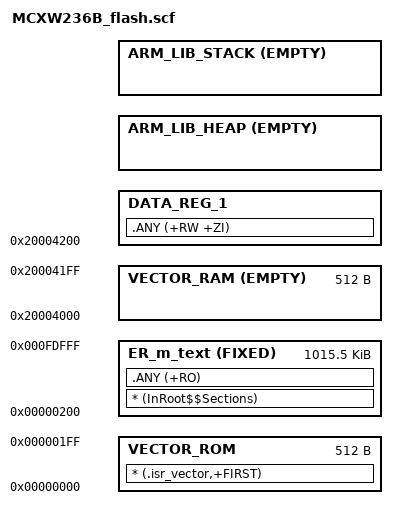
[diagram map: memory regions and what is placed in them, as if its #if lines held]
#!armclang --target=arm-arm-none-eabi -march=armv8-m.main -E -x c
/*
** ###################################################################
**     Processors:          MCXW236BIHNAR
**                          MCXW236BIUKAR
**
**     Compiler:            Keil ARM C/C++ Compiler
**     Reference manual:    MCXW23x User manual Rev.0.1  1 September 2022
**     Version:             rev. 1.0, 2022-03-08
**     Build:               b241118
**
**     Abstract:
**         Linker file for the Keil ARM C/C++ Compiler
**
**     Copyright 2016 Freescale Semiconductor, Inc.
**     Copyright 2016-2025 NXP
**     SPDX-License-Identifier: BSD-3-Clause
**
**     http:                 www.nxp.com
**     mail:                 support@nxp.com
**
** ###################################################################
*/


/* Sizes */
#if (defined(__stack_size__))
  #define Stack_Size                   __stack_size__
#else
  #define Stack_Size                   0x0500
#endif

#if (defined(__heap_size__))
  #define Heap_Size                    __heap_size__
#else
  #define Heap_Size                    0x0400
#endif

#define __ram_vector_table_size__      0x00000200

#define  m_interrupts_start            0x00000000
#define  m_interrupts_size             0x00000200

#define m_text_start                   0x00000200
#define m_text_size                    0x000FDE00

#define m_interrupts_ram_start         0x20004000
#define m_interrupts_ram_size          __ram_vector_table_size__

/* 112k (SRAM0 = 16k, SRAM1 = 32k, SRAM2 = 64K) RAM to fit data segment */
/* First  512B (from 0x20004000 until 0x20004200) ram is used to put vector table */
/* The reset of ram is used for data memory */
#define  m_data_start                  (m_interrupts_ram_start + m_interrupts_ram_size)
#define  m_data_size                   (0x0001A000 - m_interrupts_ram_size)

LR_m_text m_interrupts_start m_interrupts_size+m_text_size {   ; load region size_region

  VECTOR_ROM m_interrupts_start m_interrupts_size { ; load address = execution address
    * (.isr_vector,+FIRST)
  }

  VECTOR_RAM m_interrupts_ram_start EMPTY m_interrupts_ram_size {
  }

  ER_m_text m_text_start FIXED m_text_size {
    * (InRoot$$Sections)
    .ANY (+RO)
  }
  DATA_REG_1 m_data_start m_data_size-Stack_Size-Heap_Size
  {
    .ANY (+RW +ZI)
  }
  ARM_LIB_HEAP +0 EMPTY Heap_Size {    ; Heap region growing up
  }
  ARM_LIB_STACK m_data_start+m_data_size EMPTY -Stack_Size { ; Stack region growing down
  }

  ScatterAssert(ImageLimit(ARM_LIB_STACK) <= 0x20020000); Check for RAM overflow. ARM_LIB_STACK is last segment in RAM, its limit may not exceed last RAM address.
}
